# VPAC0_PAR_VPAC_MSC_CFG_VP_CFG_VP register map
Vendor: Texas Instruments
Peripheral module from a debugger description file (folder J7ES).
Registers are 32-bit, read-write, reset 0x0 unless marked. A register's access mark holds for its fields unless they carry their own. Offsets are as the file gives them; lines under a group give offsets from that group; [hi:lo] are bit positions; {n}, {i} and the like mark numbered series; 'fields as' and 'values as' point back to an identical list; <NAME> marks a mode.

## VPAC0_PAR_VPAC_MSC_CFG_VP_CFG_VP
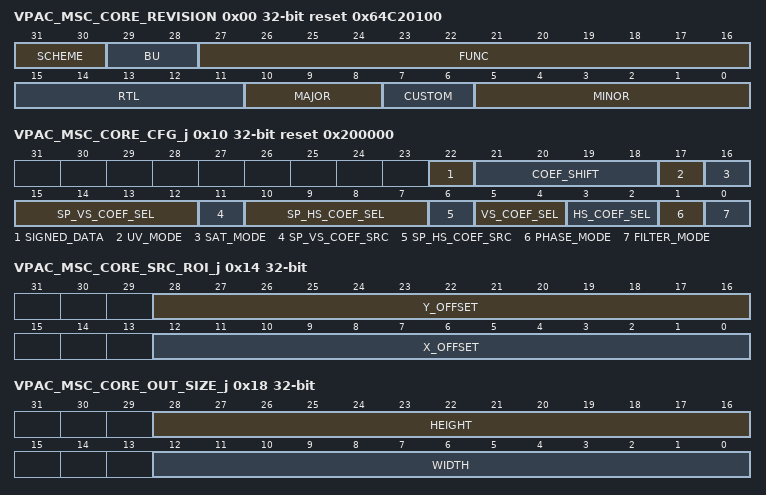
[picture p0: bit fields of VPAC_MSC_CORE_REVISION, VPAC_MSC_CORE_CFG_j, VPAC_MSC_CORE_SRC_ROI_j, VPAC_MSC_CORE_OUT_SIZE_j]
0x00 VPAC_MSC_CORE_REVISION ro reset 0x64C20100 — The Register contains the major and minor revisions for the VPAC MSC HWA module.
  [31:30] SCHEME — Used to distinguish between old scheme and new scheme.
  [29:28] BU — BU indicator DSPS ==&gt; 0x0 WTBU ==&gt; 0x1 Processors ==&gt; 0x2
  [27:16] FUNC — Function indicates a software compatible module family.
  [15:11] RTL — RTL Version.
  [10:8] MAJOR
  [7:6] CUSTOM — Indicates a special version for a particular device.
  [5:0] MINOR
0x04 VPAC_MSC_CORE_CONTROL — The Register allows the CPU to various aspects of the module.
  [0] MSC_ENABLE — MSC Core Enable: Enables the MSC HWA.
0x10 VPAC_MSC_CORE_CFG_j reset 0x200000 — The FILT[a]_CFG register configures the modes of FILTER channel [a]. Offset = 001C0010h + (j * 20h); where j = 0h to 9h
  [22] SIGNED_DATA — Integer type of input and output frame data:
  [21:18] COEF_SHIFT — Coef Shift Size: configures the precision of the
  [17] UV_MODE — Source data interleave format:
  [16] SAT_MODE — Filter Output Saturation Mode
  [15:12] SP_VS_COEF_SEL — Single Phase Vertical Filter Coef Selection (sp_vs_coef_src = 0)
  [11] SP_VS_COEF_SRC — Single Phase Vertical Filter Coef Source Selection
  [10:7] SP_HS_COEF_SEL — Single Phase Horizontal Filter Coef Selection (sp_hs_coef_src = 0)
  [6] SP_HS_COEF_SRC — Single Phase Horizontal Filter Coef Source Selection
  [5:4] VS_COEF_SEL — Multi-phase Vertical Coef Selection (Phase_mode=0)
  [3:2] HS_COEF_SEL — Multi-phase Horizontal Coef Selection (Phase_mode=0)
  [1] PHASE_MODE — Filter Phase mode selection
  [0] FILTER_MODE
0x14 VPAC_MSC_CORE_SRC_ROI_j — The FILT[a]_SRC_ROI register configures the input ROI position within the input super frame for FILTER channel [a]. Set to 0 if ROI is full-size. Offset = 001C0014h + (j * 20h); where j = 0h to 9h
  [28:16] Y_OFFSET — Source Y offset
  [12:0] X_OFFSET — Source X offset (Must be an even # when FILT_CFG.uv_mode=1)
0x18 VPAC_MSC_CORE_OUT_SIZE_j — The FILT[a]_OUT_SIZE configures the output size for FILTER channel [a]. Offset = 001C0018h + (j * 20h); where j = 0h to 9h
  [28:16] HEIGHT — Output Height
  [12:0] WIDTH — Output Width
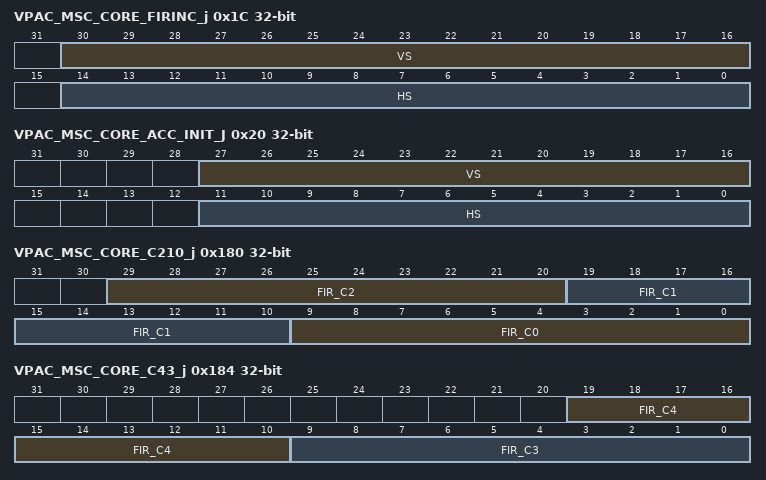
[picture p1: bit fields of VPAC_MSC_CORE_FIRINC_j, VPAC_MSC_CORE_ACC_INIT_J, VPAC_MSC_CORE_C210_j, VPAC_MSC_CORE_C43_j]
0x1C VPAC_MSC_CORE_FIRINC_j — The FILT[a]_FIRINC register configures the FIRINC attributes of FILTER channel [a]. Offset = 001C001Ch + (j * 20h); where j = 0h to 9h
  [30:16] VS — FIRINC of VS filter
  [14:0] HS — FIRINC of HS filter
0x20 VPAC_MSC_CORE_ACC_INIT_J — The FILT[a]_ACC_INIT register configures the FIRINC attributes of FILTER channel [a]. Offset = 001C0020h + (j * 20h); where j = 0h to 9h
  [27:16] VS — ACC_INIT of VS filter
  [11:0] HS — ACC_INIT of HS filter
0x180 VPAC_MSC_CORE_C210_j — Single Phase Coef Set[a] coefficients C2/C1/C0 Offset = 001C0180h + (j * 8h); where j = 0h to 1h
  [29:20] FIR_C2 — Signed coefficient C2
  [19:10] FIR_C1 — Signed coefficient C1
  [9:0] FIR_C0 — Signed coefficient C0
0x184 VPAC_MSC_CORE_C43_j — Single Phase Coef Set[a] coefficients C4/C3 Offset = 001C0184h + (j * 8h); where j = 0h to 1h
  [19:10] FIR_C4 — Signed coefficient C4
  [9:0] FIR_C3 — Signed coefficient C3
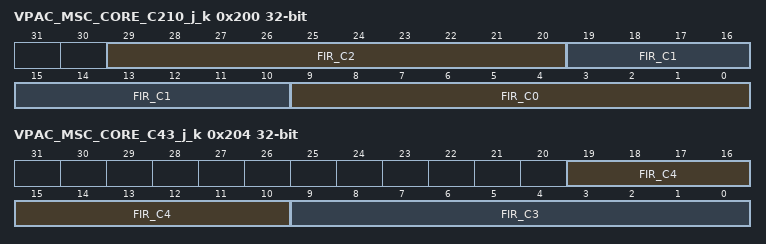
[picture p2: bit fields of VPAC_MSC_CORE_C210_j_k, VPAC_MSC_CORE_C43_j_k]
0x200 VPAC_MSC_CORE_C210_j_k — Multi Phase Coef Set[a] Phase[b] coefficients C2/C1/C0 Offset = 001C0200h + (j * 100h) + (k * 8h); where j = 0h to 3h, k = 0h to 1Fh
  fields as VPAC_MSC_CORE_C210_j
0x204 VPAC_MSC_CORE_C43_j_k — Multi Phase Coef Set[a] Phase[b] coefficients C4/C3 Offset = 001C0204h + (j * 100h) + (k * 8h); where j = 0h to 3h, k = 0h to 1Fh
  fields as VPAC_MSC_CORE_C43_j
